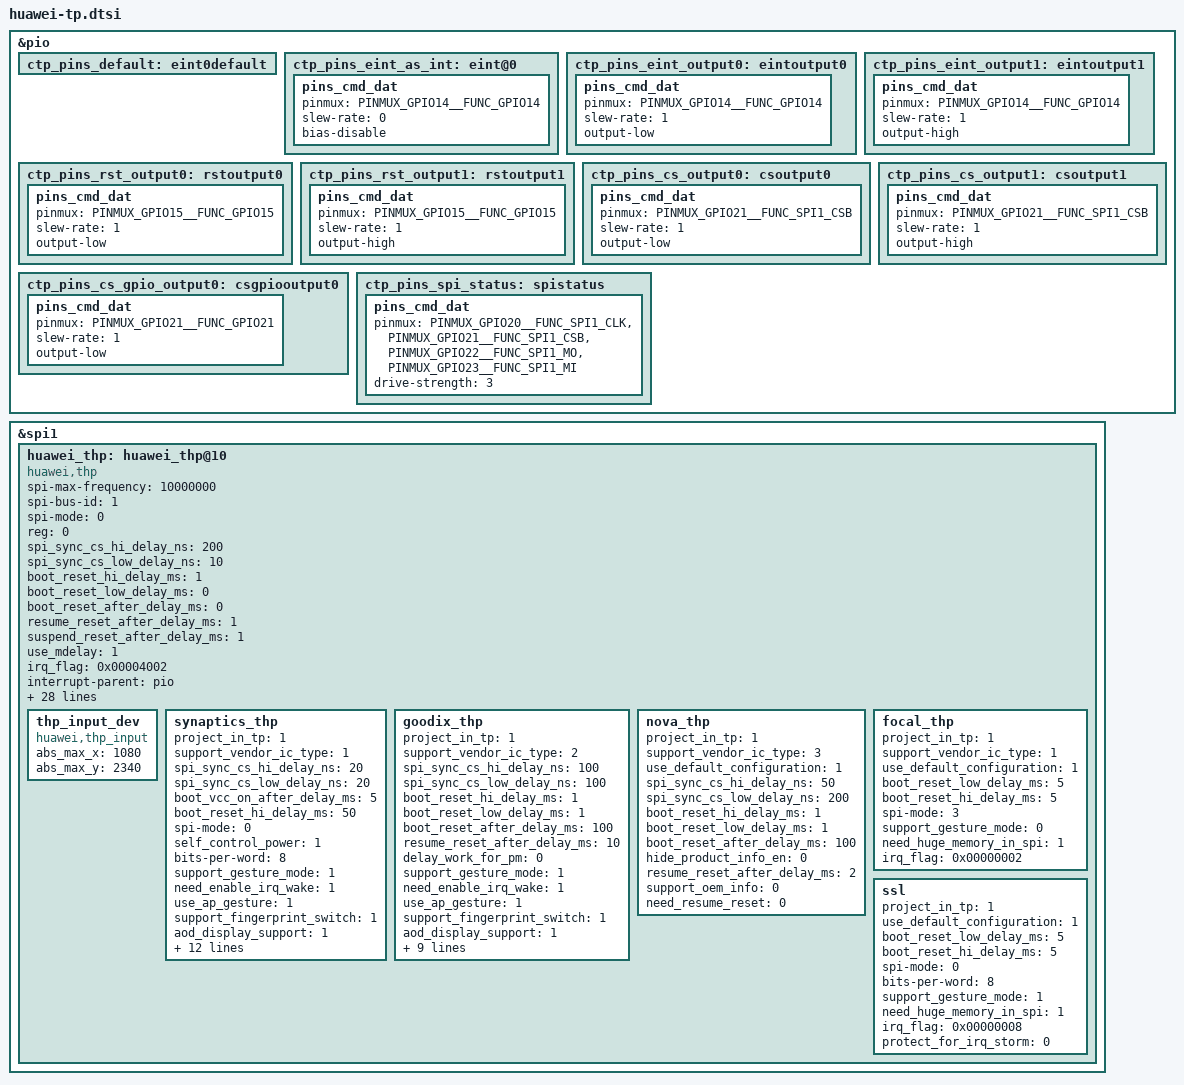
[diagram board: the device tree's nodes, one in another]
&pio {
	ctp_pins_default: eint0default {
	};
	ctp_pins_eint_as_int: eint@0 {
		pins_cmd_dat {
			pinmux = <PINMUX_GPIO14__FUNC_GPIO14>;
			slew-rate = <0>;
			bias-disable;
		};
	};
	ctp_pins_eint_output0: eintoutput0 {
		pins_cmd_dat {
			pinmux = <PINMUX_GPIO14__FUNC_GPIO14>;
			slew-rate = <1>;
			output-low;
		};
	};
	ctp_pins_eint_output1: eintoutput1 {
		pins_cmd_dat {
			pinmux = <PINMUX_GPIO14__FUNC_GPIO14>;
			slew-rate = <1>;
			output-high;
		};
	};
	ctp_pins_rst_output0: rstoutput0 {
		pins_cmd_dat {
			pinmux = <PINMUX_GPIO15__FUNC_GPIO15>;
			slew-rate = <1>;
			output-low;
		};
	};
	ctp_pins_rst_output1: rstoutput1 {
		pins_cmd_dat {
			pinmux = <PINMUX_GPIO15__FUNC_GPIO15>;
			slew-rate = <1>;
			output-high;
		};
	};

	ctp_pins_cs_output0: csoutput0 {
		pins_cmd_dat {
			pinmux = <PINMUX_GPIO21__FUNC_SPI1_CSB>;
			slew-rate = <1>;
			output-low;
		};
	};
	ctp_pins_cs_output1: csoutput1 {
		pins_cmd_dat {
			pinmux = <PINMUX_GPIO21__FUNC_SPI1_CSB>;
			slew-rate = <1>;
			output-high;
		};
	};
	ctp_pins_cs_gpio_output0: csgpiooutput0 {
		pins_cmd_dat {
			pinmux = <PINMUX_GPIO21__FUNC_GPIO21>;
			slew-rate = <1>;
			output-low;
		};
	};
	ctp_pins_spi_status: spistatus {
		pins_cmd_dat {
			pinmux = <PINMUX_GPIO20__FUNC_SPI1_CLK>,
				 <PINMUX_GPIO21__FUNC_SPI1_CSB>,
				 <PINMUX_GPIO22__FUNC_SPI1_MO>,
				 <PINMUX_GPIO23__FUNC_SPI1_MI>;
			drive-strength = <3>;
		};
	};
};

&spi1 {
	status = "ok";
	#address-cells = <1>;
	#size-cells = <0>;
	huawei_thp: huawei_thp@10 {
		compatible = "huawei,thp";
		/* SPI Config */
		spi-max-frequency = <10000000>;
		spi-bus-id = <1>;
		spi-mode = <0>;
		reg = <0>;
		spi_sync_cs_hi_delay_ns = <200>;
		spi_sync_cs_low_delay_ns = <10>;
		/* Timing */
		boot_reset_hi_delay_ms = <1>;
		boot_reset_low_delay_ms = <0>;
		boot_reset_after_delay_ms = <0>;
		resume_reset_after_delay_ms = <1>;
		suspend_reset_after_delay_ms = <1>;
		use_mdelay = <1>;
		/* GPIO Config */
		irq_flag = <0x00004002>;
		interrupt-parent = <&pio>;
		interrupts = <14 2 0 0>;
		thp-vcc-type = <1>; /* 0-unsued 1-ldo 2-gpio */
		thp-vcc-supply = <&mt_pmic_vtp_ldo_reg>;
		thp-vcc-value = <3100000>;
		//thp-iovdd-type = <2>;
		//thp-iovdd-gpio = <&pio 137 0>;
		//thp-iovdd-value = <1800000>;
		/* PinCtrl Config */
		support_pinctrl = <1>;
		pinctrl-names = "default", "idle", "state_eint_as_int", "state_rst_output0",
			"state_rst_output1", "state_cs_output0", "state_cs_output1", "state_spi_status";
		pinctrl-0 = <&ctp_pins_rst_output1 &ctp_pins_cs_output1>;
		pinctrl-1 = <&ctp_pins_rst_output0 &ctp_pins_cs_gpio_output0>;
		pinctrl-2 = <&ctp_pins_eint_as_int>;
		pinctrl-3 = <&ctp_pins_rst_output0>;
		pinctrl-4 = <&ctp_pins_rst_output1>;
		pinctrl-5 = <&ctp_pins_cs_output0>;
		pinctrl-6 = <&ctp_pins_cs_output1>;
		pinctrl-7 = <&ctp_pins_spi_status>;
		/* Feature Config */
		pt_station_test = <1>;
		proximity_support = <0>;
		hide_product_info_en = <1>;
		support_no_cs_pinctrl_for_mtk = <0>;
		support_control_cs_off = <1>;
		change_spi_driving_force = <1>;
		support_gesture_mode = <1>;
		use_ap_gesture = <1>;
		support_fingerprint_switch = <1>;
		need_enable_irq_wake = <1>;
		fast_booting_solution = <1>;
		supported_charger = <1>;
		need_notify_to_roi_algo = <1>;

		thp_input_dev {
			compatible = "huawei,thp_input";
			abs_max_x = <1080>;
			abs_max_y = <2340>;
		};
		synaptics_thp {
			project_in_tp = <1>;
			support_vendor_ic_type = <1>;
			spi_sync_cs_hi_delay_ns = <20>;
			spi_sync_cs_low_delay_ns = <20>;
			boot_vcc_on_after_delay_ms = <5>;
			boot_reset_hi_delay_ms = <50>;
			spi-mode = <0>;
			self_control_power = <1>;
			bits-per-word = <8>;
			support_gesture_mode = <1>;
			need_enable_irq_wake = <1>;
			use_ap_gesture = <1>;
			support_fingerprint_switch = <1>;
			aod_display_support = <1>;
			need_huge_memory_in_spi = <1>;
			edit_product_in_project_id = <1>;
			use_aod_power_ctrl_notify = <1>;
			suspend_delayms_early_to_before = <150>;
			suspend_delayms_before_to_later = <15>;
			resume_delayms_early_to_later = <150>;
			product = "B20A";
			/* IRQF_TRIGGER_LOW 0x00000008 */
			irq_flag = <0x00000008>;
			support_get_frame_read_once = <1>;
			send_one_cmd_for_ap = <1>;
			change_spi_driving_force = <1>;
			support_deepsleep_mode = <1>;
		};
		goodix_thp {
			project_in_tp = <1>;
			support_vendor_ic_type = <2>;
			spi_sync_cs_hi_delay_ns = <100>;
			spi_sync_cs_low_delay_ns = <100>;
			boot_reset_hi_delay_ms = <1>;
			boot_reset_low_delay_ms = <1>;
			boot_reset_after_delay_ms = <100>;
			resume_reset_after_delay_ms = <10>;
			delay_work_for_pm = <0>;
			support_gesture_mode = <1>;
			need_enable_irq_wake = <1>;
			use_ap_gesture = <1>;
			support_fingerprint_switch = <1>;
			aod_display_support = <1>;
			support_oem_info = <0>;
			need_resume_reset = <0>;
			gesture_mode_double_tap = <1>;
			edit_product_in_project_id = <1>;
			product = "B20A";
			use_aod_power_ctrl_notify = <1>;
			suspend_delayms_early_to_before = <150>;
			suspend_delayms_before_to_later = <15>;
			resume_delayms_early_to_later = <150>;
		};
		nova_thp {
			project_in_tp = <1>;
			support_vendor_ic_type = <3>;
			use_default_configuration = <1>;
			spi_sync_cs_hi_delay_ns = <50>;
			spi_sync_cs_low_delay_ns = <200>;
			boot_reset_hi_delay_ms = <1>;
			boot_reset_low_delay_ms = <1>;
			boot_reset_after_delay_ms = <100>;
			hide_product_info_en = <0>;
			resume_reset_after_delay_ms = <2>;
			support_oem_info = <0>;
			need_resume_reset = <0>;
		};
		focal_thp {
			project_in_tp = <1>;
			support_vendor_ic_type = <1>;
			use_default_configuration = <1>;
			boot_reset_low_delay_ms = <5>;
			boot_reset_hi_delay_ms = <5>;
			spi-mode = <3>;
			support_gesture_mode = <0>;
			need_huge_memory_in_spi = <1>;
			/* IRQF_TRIGGER_FALL 0x00000002 */
			irq_flag = <0x00000002>;
		};
		ssl {
			project_in_tp = <1>;
			use_default_configuration = <1>;
			boot_reset_low_delay_ms = <5>;
			boot_reset_hi_delay_ms = <5>;
			spi-mode = <0>;
			bits-per-word = <8>;
			support_gesture_mode = <1>;
			need_huge_memory_in_spi = <1>;
			/* IRQF_TRIGGER_LOW 0x00000008 */
			irq_flag = <0x00000008>;
			protect_for_irq_storm = <0>;
		};
	};
};
